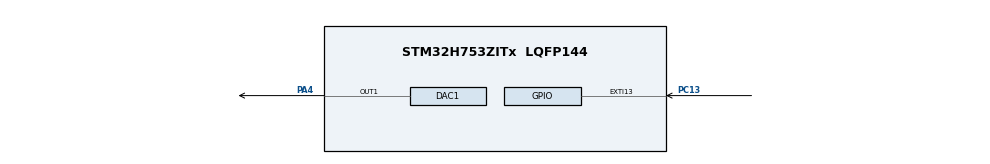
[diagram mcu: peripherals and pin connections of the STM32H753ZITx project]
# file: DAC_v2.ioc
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CORTEX_M7.CPU_DCache=Disabled
CORTEX_M7.CPU_ICache=Disabled
CORTEX_M7.MPU_Control=__NULL
CORTEX_M7.default_mode_Activation=1
DAC1.DAC_Channel-DAC_OUT1=DAC_CHANNEL_1
DAC1.DAC_Trigger-DAC_OUT1=DAC_TRIGGER_T6_TRGO
Dma.DAC1_CH1.0.Direction=DMA_MEMORY_TO_PERIPH
Dma.DAC1_CH1.0.EventEnable=DISABLE
Dma.DAC1_CH1.0.FIFOMode=DMA_FIFOMODE_DISABLE
Dma.DAC1_CH1.0.Instance=DMA1_Stream0
Dma.DAC1_CH1.0.MemDataAlignment=DMA_MDATAALIGN_HALFWORD
Dma.DAC1_CH1.0.MemInc=DMA_MINC_ENABLE
Dma.DAC1_CH1.0.Mode=DMA_CIRCULAR
Dma.DAC1_CH1.0.PeriphDataAlignment=DMA_PDATAALIGN_HALFWORD
Dma.DAC1_CH1.0.PeriphInc=DMA_PINC_DISABLE
Dma.DAC1_CH1.0.Polarity=HAL_DMAMUX_REQ_GEN_RISING
Dma.DAC1_CH1.0.Priority=DMA_PRIORITY_LOW
Dma.DAC1_CH1.0.RequestNumber=1
Dma.DAC1_CH1.0.SignalID=NONE
Dma.DAC1_CH1.0.SyncEnable=DISABLE
Dma.DAC1_CH1.0.SyncPolarity=HAL_DMAMUX_SYNC_NO_EVENT
Dma.DAC1_CH1.0.SyncRequestNumber=1
Dma.DAC1_CH1.0.SyncSignalID=NONE
Dma.Request0=DAC1_CH1
Mcu.Family=STM32H7
Mcu.Name=STM32H753ZITx
Mcu.Package=LQFP144
NUCLEO-H753ZI.BUTTON=1
NVIC.DMA1_Stream0_IRQn=true\:0\:0\:false\:false\:true\:false\:true\:true
NVIC.EXTI15_10_IRQn=true\:0\:0\:false\:false\:true\:false\:true\:true
NVIC.PriorityGroup=NVIC_PRIORITYGROUP_4
PA4.Signal=COMP_DAC11_group
PC13.Signal=GPXTI13
ProjectManager.HeapSize=0x200
ProjectManager.StackSize=0x400
ProjectManager.TargetToolchain=STM32CubeIDE
RCC.ADCFreq_Value=129000000
RCC.APB1Freq_Value=64000000
RCC.APB2Freq_Value=64000000
RCC.APB3Freq_Value=64000000
RCC.APB4Freq_Value=64000000
RCC.CortexFreq_Value=64000000
RCC.DIVM1=1
RCC.DIVN1=24
RCC.DIVQ1=4
RCC.HCLKFreq_Value=64000000
RCC.HSE_VALUE=8000000
RCC.PLLFRACN=0
RCC.PWR_Regulator_Voltage_Scale=PWR_REGULATOR_VOLTAGE_SCALE2
RCC.SYSCLKFreq_VALUE=64000000
RCC.USBFreq_Value=384000000
SH.COMP_DAC11_group.0=DAC1_OUT1,DAC_OUT1
TIM6.Period=100-1
TIM6.Prescaler=400-1
TIM6.TIM_MasterOutputTrigger=TIM_TRGO_UPDATE
VP_MEMORYMAP_VS_MEMORYMAP.Mode=CurAppReg
VP_NUCLEO-H753ZI_VS_BSP_COMMON.Mode=COMMON
VP_TIM6_VS_ClockSourceINT.Mode=Enable_Timer
board=NUCLEO-H753ZI

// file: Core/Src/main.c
/* USER CODE BEGIN Header */
/**
  ******************************************************************************
  * @file           : main.c
  * @brief          : Main program body
  ******************************************************************************
  * @attention
  *
  * Copyright (c) 2026 STMicroelectronics.
  * All rights reserved.
  *
  * This software is licensed under terms that can be found in the LICENSE file
  * in the root directory of this software component.
  * If no LICENSE file comes with this software, it is provided AS-IS.
  *
  ******************************************************************************
  */
/* USER CODE END Header */
#include "main.h"

/* USER CODE BEGIN Includes */
#include <math.h>
/* USER CODE END Includes */

/* USER CODE BEGIN PD */
#define SAMPLES 100
/* USER CODE END PD */

DAC_HandleTypeDef hdac1;
DMA_HandleTypeDef hdma_dac1_ch1;

TIM_HandleTypeDef htim6;

/* USER CODE BEGIN PV */

uint16_t sine_val[SAMPLES];
uint16_t cos_val[SAMPLES];
uint16_t tri_val[SAMPLES];
uint16_t square_val[SAMPLES];

volatile uint8_t  current_wave_type = 0; // 0:Sin, 1:Cos, 2:Tri, 3:Squ
volatile float    current_voltage   = 1.5f;
volatile uint32_t current_frequency = 200;

//volatile uint8_t wave_type = 0;
/* USER CODE END PV */

void SystemClock_Config(void);
static void MX_GPIO_Init(void);
static void MX_DMA_Init(void);
static void MX_DAC1_Init(void);
static void MX_TIM6_Init(void);

/* USER CODE BEGIN 0 */

/**
  * @brief  Dizileri verilen voltaj değerine göre yeniden hesaplar.
  */
void Set_Wave_Amplitude(float target_voltage) {
    if (target_voltage > 3.5f) target_voltage = 3.5f;
    if (target_voltage < 0.0f) target_voltage = 0.0f;

    current_voltage = target_voltage; // Durumu guncelle

    float amplitude = (target_voltage / 3.5f) * 4095.0f;
    float offset = amplitude / 2.0f;

    for (int i = 0; i < SAMPLES; i++) {
        sine_val[i]   = (uint16_t)((sin(i * 2 * M_PI / SAMPLES) * offset) + offset);
        cos_val[i]    = (uint16_t)((cos(i * 2 * M_PI / SAMPLES) * offset) + offset);

        if (i < SAMPLES / 2) {
            tri_val[i] = (uint16_t)((i * amplitude) / (SAMPLES / 2));
            square_val[i] = (uint16_t)amplitude;
        } else {
            tri_val[i] = (uint16_t)(amplitude - ((i - SAMPLES / 2) * amplitude) / (SAMPLES / 2));
            square_val[i] = 0;
        }
    }
}

/**
  * @brief  Timer ARR değerini hedef frekansa göre ayarlar.
  */
void Set_Wave_Frequency(uint32_t target_hz) {
    if (target_hz == 0) return;
    current_frequency = target_hz; // Durumu guncelle

    uint32_t timer_clock = 64000000;
    uint32_t psc_val = 400;
    uint32_t new_period = timer_clock / (psc_val * SAMPLES * target_hz);

    if (new_period < 1) new_period = 1;
    if (new_period > 65535) new_period = 65535;

    __HAL_TIM_SET_AUTORELOAD(&htim6, (new_period - 1));
}

/**
  * @brief  DAC ve DMA'yı mevcut ayarlara göre yeniden başlatır.
  */
void Update_Wave_Output(void) {
    // 1. DMA'yı durdur
    HAL_DAC_Stop_DMA(&hdac1, DAC_CHANNEL_1);

    // 2. Hangi dizi gönderilecek seç
    uint16_t *pWave;
    switch (current_wave_type) {
        case 0:  pWave = sine_val;   break;
        case 1:  pWave = cos_val;    break;
        case 2:  pWave = tri_val;    break;
        case 3:  pWave = square_val; break;
        default: pWave = sine_val;   break;
    }

    // 3. DMA'yı tekrar başlat
    HAL_DAC_Start_DMA(&hdac1, DAC_CHANNEL_1, (uint32_t*)pWave, SAMPLES, DAC_ALIGN_12B_R);
}
/* USER CODE END 0 */

int main(void)
{

  /* MCU Configuration--------------------------------------------------------*/

  /* Reset of all peripherals, Initializes the Flash interface and the Systick. */
  HAL_Init();

  /* Configure the system clock */
  SystemClock_Config();

  /* Initialize all configured peripherals */
  MX_GPIO_Init();
  MX_DMA_Init();
  MX_DAC1_Init();
  MX_TIM6_Init();
  /* USER CODE BEGIN 2 */

  // Başlangıç Kurulumu
    Set_Wave_Amplitude(0.5);
    Set_Wave_Frequency(250);
    HAL_TIM_Base_Start(&htim6);

    Update_Wave_Output();
  /* USER CODE END 2 */

  /* Initialize USER push-button, will be used to trigger an interrupt each time it's pressed.*/

  /* Infinite loop */
  while (1)
  {

  }
}

void SystemClock_Config(void)
{
  RCC_OscInitTypeDef RCC_OscInitStruct = {0};
  RCC_ClkInitTypeDef RCC_ClkInitStruct = {0};

  /** Supply configuration update enable
  */
  HAL_PWREx_ConfigSupply(PWR_LDO_SUPPLY);

  /** Configure the main internal regulator output voltage
  */
  __HAL_PWR_VOLTAGESCALING_CONFIG(PWR_REGULATOR_VOLTAGE_SCALE2);

  while(!__HAL_PWR_GET_FLAG(PWR_FLAG_VOSRDY)) {}

  /** Initializes the RCC Oscillators according to the specified parameters
  * in the RCC_OscInitTypeDef structure.
  */
  RCC_OscInitStruct.OscillatorType = RCC_OSCILLATORTYPE_HSI;
  RCC_OscInitStruct.HSIState = RCC_HSI_DIV1;
  RCC_OscInitStruct.HSICalibrationValue = RCC_HSICALIBRATION_DEFAULT;
  RCC_OscInitStruct.PLL.PLLState = RCC_PLL_NONE;
  if (HAL_RCC_OscConfig(&RCC_OscInitStruct) != HAL_OK)
  {
    Error_Handler();
  }

  /** Initializes the CPU, AHB and APB buses clocks
  */
  RCC_ClkInitStruct.ClockType = RCC_CLOCKTYPE_HCLK|RCC_CLOCKTYPE_SYSCLK
                              |RCC_CLOCKTYPE_PCLK1|RCC_CLOCKTYPE_PCLK2
                              |RCC_CLOCKTYPE_D3PCLK1|RCC_CLOCKTYPE_D1PCLK1;
  RCC_ClkInitStruct.SYSCLKSource = RCC_SYSCLKSOURCE_HSI;
  RCC_ClkInitStruct.SYSCLKDivider = RCC_SYSCLK_DIV1;
  RCC_ClkInitStruct.AHBCLKDivider = RCC_HCLK_DIV1;
  RCC_ClkInitStruct.APB3CLKDivider = RCC_APB3_DIV1;
  RCC_ClkInitStruct.APB1CLKDivider = RCC_APB1_DIV1;
  RCC_ClkInitStruct.APB2CLKDivider = RCC_APB2_DIV1;
  RCC_ClkInitStruct.APB4CLKDivider = RCC_APB4_DIV1;

  if (HAL_RCC_ClockConfig(&RCC_ClkInitStruct, FLASH_LATENCY_1) != HAL_OK)
  {
    Error_Handler();
  }
}

static void MX_DAC1_Init(void)
{

  DAC_ChannelConfTypeDef sConfig = {0};

  /** DAC Initialization
  */
  hdac1.Instance = DAC1;
  if (HAL_DAC_Init(&hdac1) != HAL_OK)
  {
    Error_Handler();
  }

  /** DAC channel OUT1 config
  */
  sConfig.DAC_SampleAndHold = DAC_SAMPLEANDHOLD_DISABLE;
  sConfig.DAC_Trigger = DAC_TRIGGER_T6_TRGO;
  sConfig.DAC_OutputBuffer = DAC_OUTPUTBUFFER_ENABLE;
  sConfig.DAC_ConnectOnChipPeripheral = DAC_CHIPCONNECT_DISABLE;
  sConfig.DAC_UserTrimming = DAC_TRIMMING_FACTORY;
  if (HAL_DAC_ConfigChannel(&hdac1, &sConfig, DAC_CHANNEL_1) != HAL_OK)
  {
    Error_Handler();
  }

}

static void MX_TIM6_Init(void)
{

  TIM_MasterConfigTypeDef sMasterConfig = {0};

  htim6.Instance = TIM6;
  htim6.Init.Prescaler = 400-1;
  htim6.Init.CounterMode = TIM_COUNTERMODE_UP;
  htim6.Init.Period = 100-1;
  htim6.Init.AutoReloadPreload = TIM_AUTORELOAD_PRELOAD_DISABLE;
  if (HAL_TIM_Base_Init(&htim6) != HAL_OK)
  {
    Error_Handler();
  }
  sMasterConfig.MasterOutputTrigger = TIM_TRGO_UPDATE;
  sMasterConfig.MasterSlaveMode = TIM_MASTERSLAVEMODE_DISABLE;
  if (HAL_TIMEx_MasterConfigSynchronization(&htim6, &sMasterConfig) != HAL_OK)
  {
    Error_Handler();
  }

}

static void MX_DMA_Init(void)
{

  /* DMA controller clock enable */
  __HAL_RCC_DMA1_CLK_ENABLE();

  /* DMA interrupt init */
  /* DMA1_Stream0_IRQn interrupt configuration */
  HAL_NVIC_SetPriority(DMA1_Stream0_IRQn, 0, 0);
  HAL_NVIC_EnableIRQ(DMA1_Stream0_IRQn);

}

static void MX_GPIO_Init(void)
{
  GPIO_InitTypeDef GPIO_InitStruct = {0};

  /* GPIO Ports Clock Enable */
  __HAL_RCC_GPIOC_CLK_ENABLE();
  __HAL_RCC_GPIOA_CLK_ENABLE();

  /*Configure GPIO pin : PC13 */
  GPIO_InitStruct.Pin = GPIO_PIN_13;
  GPIO_InitStruct.Mode = GPIO_MODE_IT_RISING;
  GPIO_InitStruct.Pull = GPIO_NOPULL;
  HAL_GPIO_Init(GPIOC, &GPIO_InitStruct);

  /* EXTI interrupt init*/
  HAL_NVIC_SetPriority(EXTI15_10_IRQn, 0, 0);
  HAL_NVIC_EnableIRQ(EXTI15_10_IRQn);

}

/* USER CODE BEGIN 4 */
void HAL_GPIO_EXTI_Callback(uint16_t GPIO_Pin) {
    if (GPIO_Pin == GPIO_PIN_13) {
        // Sadece dalga tipini değiştir ve çıkışı tazele
        current_wave_type = (current_wave_type + 1) % 4;
        Update_Wave_Output();
    }
}

/* USER CODE END 4 */

void Error_Handler(void)
{
  __disable_irq();
  while (1)
  {
  }
}
